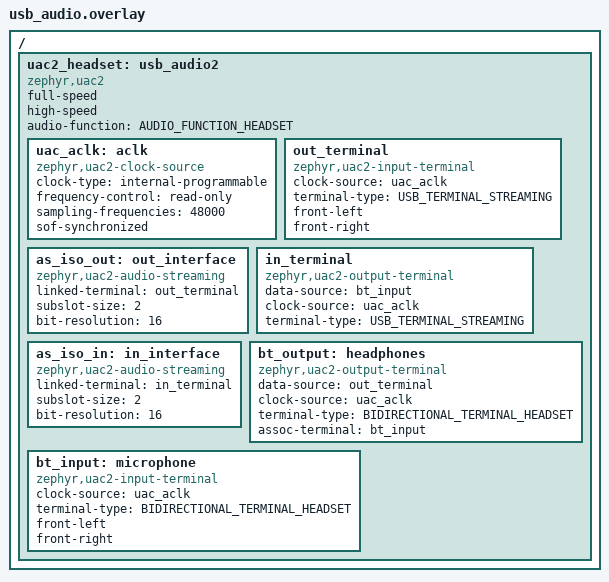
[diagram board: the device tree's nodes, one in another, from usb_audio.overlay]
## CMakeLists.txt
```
# SPDX-License-Identifier: Apache-2.0

cmake_minimum_required(VERSION 3.28.0)
find_package(Zephyr REQUIRED HINTS $ENV{ZEPHYR_BASE})
project(bluetooth_shell)

zephyr_library_include_directories(${ZEPHYR_BASE}/samples/bluetooth)

target_sources(app PRIVATE src/main.c)
```

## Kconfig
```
# Copyright (c) 2026 Nordic Semiconductor ASA
# SPDX-License-Identifier: Apache-2.0

mainmenu "Bluetooth Shell Test Application"

# LE Audio Controller settings for non-network core devices
if BT_AUDIO && BT_LL_SW_SPLIT

configdefault BT_CTLR_DATA_LENGTH_MAX
	default 251

# Set to high value to support large BASEs + extra data
configdefault BT_CTLR_SCAN_DATA_LEN_MAX
	default 1650

configdefault BT_CTLR_ADV_SYNC_SET
	default BT_CTLR_ADV_AUX_SET

configdefault BT_CTLR_ADV_DATA_LEN_MAX
	default 191

configdefault BT_CTLR_ADV_DATA_BUF_MAX
	default 6

# Match BT_BAP_BROADCAST_SRC_STREAM_COUNT in audio.conf
configdefault BT_CTLR_SYNC_ISO_STREAM_MAX
	default 2

# Match BT_BAP_BROADCAST_SNK_STREAM_COUNT in audio.conf
configdefault BT_CTLR_ADV_ISO_STREAM_MAX
	default 2

# Match BT_BAP_UNICAST_CLIENT_ASE_SRC_COUNT/BT_ASCS_MAX_ASE_SNK_COUNT audio.conf
configdefault BT_CTLR_ISOAL_SOURCES
	default 2

# BT_BAP_UNICAST_CLIENT_ASE_SNK_COUNT/BT_ASCS_MAX_ASE_SRC_COUNT in audio.conf
configdefault BT_CTLR_ISOAL_SINKS
	default 2

configdefault BT_CTLR_ISO_TX_BUFFER_SIZE
	default 255

configdefault BT_CTLR_ISO_TX_SDU_LEN_MAX
	default 247

endif # BT_AUDIO && BT_LL_SW_SPLIT

source "Kconfig.zephyr"
```

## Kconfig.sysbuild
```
# Copyright 2023-2024 Nordic Semiconductor ASA
# SPDX-License-Identifier: Apache-2.0

source "share/sysbuild/Kconfig"

config NET_CORE_BOARD
	string
	default "nrf5340dk/nrf5340/cpunet" if $(BOARD) = "nrf5340dk"
	default "nrf5340_audio_dk/nrf5340/cpunet" if $(BOARD) = "nrf5340_audio_dk"
	default "nrf5340bsim/nrf5340/cpunet" if $(BOARD_TARGET_STRING) = "NRF5340BSIM_NRF5340_CPUAPP"

config NET_CORE_IMAGE_HCI_IPC
	bool "HCI IPC image on network core"
	default y
	depends on NET_CORE_BOARD != ""
```

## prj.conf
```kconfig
CONFIG_TEST=y
CONFIG_TEST_LOGGING_DEFAULTS=n
CONFIG_BT=y
CONFIG_LOG=y
CONFIG_BT_CENTRAL=y
CONFIG_BT_PERIPHERAL=y
CONFIG_BT_PRIVACY=y
CONFIG_BT_SMP=y
CONFIG_BT_PASSKEY_KEYPRESS=y
CONFIG_BT_APP_PASSKEY=y
CONFIG_BT_ATT_PREPARE_COUNT=2
CONFIG_BT_GATT_CLIENT=y
CONFIG_BT_L2CAP_DYNAMIC_CHANNEL=y
CONFIG_BT_SHELL=y
CONFIG_BT_DEVICE_NAME="test shell"
CONFIG_BT_DEVICE_NAME_DYNAMIC=y
CONFIG_BT_L2CAP_TX_BUF_COUNT=4
CONFIG_BT_ID_MAX=2
CONFIG_BT_EATT=y
CONFIG_BT_L2CAP_ECRED=y
CONFIG_BT_GATT_DYNAMIC_DB=y
CONFIG_BT_GATT_NOTIFY_MULTIPLE=y
CONFIG_BT_HRS=y
CONFIG_BT_FILTER_ACCEPT_LIST=y
CONFIG_BT_REMOTE_INFO=y
CONFIG_BT_REMOTE_VERSION=y
CONFIG_BT_GATT_AUTO_DISCOVER_CCC=y

CONFIG_BT_SETTINGS=y
CONFIG_FLASH=y
CONFIG_FLASH_MAP=y
CONFIG_NVS=y
CONFIG_SETTINGS=y

CONFIG_BT_EXT_ADV=y
CONFIG_BT_EXT_ADV_LEGACY_SUPPORT=y
CONFIG_BT_PER_ADV=y
CONFIG_BT_PER_ADV_SYNC=y

CONFIG_BT_USER_DATA_LEN_UPDATE=y
CONFIG_BT_AUTO_DATA_LEN_UPDATE=y

CONFIG_BT_EAD=y

CONFIG_BT_USER_PHY_UPDATE=y

CONFIG_BT_ISO_BROADCASTER=y
CONFIG_BT_ISO_SYNC_RECEIVER=y
CONFIG_BT_ISO_CENTRAL=y
CONFIG_BT_ISO_PERIPHERAL=y

# Usage:
# `kernel log-level modulename severity`
# e.g.,
#
# kernel log-level bt_hci_core 0
# kernel log-level bt_l2cap 2
# kernel log-level bt_att 4
CONFIG_LOG_RUNTIME_FILTERING=y
```

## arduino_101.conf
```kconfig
CONFIG_BT=y
CONFIG_CONSOLE_HANDLER=y
CONFIG_BT_DEBUG_LOG=y
CONFIG_BT_CENTRAL=y
CONFIG_BT_PERIPHERAL=y
CONFIG_BT_PRIVACY=y
CONFIG_BT_SMP=y
CONFIG_BT_SIGNING=y
CONFIG_BT_ATT_PREPARE_COUNT=2
CONFIG_BT_GATT_CLIENT=y
CONFIG_BT_L2CAP_DYNAMIC_CHANNEL=y
CONFIG_BT_TINYCRYPT_ECC=y
CONFIG_CONSOLE_SHELL=y
CONFIG_BT_SHELL=y
CONFIG_BT_DEVICE_NAME="test shell"
CONFIG_BT_HRS=y
CONFIG_BT_L2CAP_TX_BUF_COUNT=6
CONFIG_BT_INTERNAL_STORAGE=y
CONFIG_FLASH=y
CONFIG_SPI=y
CONFIG_GPIO=y
CONFIG_FILE_SYSTEM=y
CONFIG_FILE_SYSTEM_FAT=y
CONFIG_DISK_ACCESS_FLASH=y
CONFIG_FILE_SYSTEM_SHELL=y
```

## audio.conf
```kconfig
# Increased stack due to settings API usage
CONFIG_SYSTEM_WORKQUEUE_STACK_SIZE=2048

# Needed for devices with many PAC records or large BASEs
CONFIG_BT_RX_STACK_SIZE=8192

CONFIG_TEST=y
CONFIG_TEST_LOGGING_DEFAULTS=n
CONFIG_BT=y
CONFIG_BT_SMP=y
CONFIG_BT_TESTING=y
CONFIG_BT_CENTRAL=y
CONFIG_BT_ISO_CENTRAL=y
CONFIG_BT_EXT_ADV=y
CONFIG_BT_PER_ADV_SYNC=y
CONFIG_BT_ISO_SYNC_RECEIVER=y
CONFIG_BT_PERIPHERAL=y
CONFIG_BT_PRIVACY=y
CONFIG_BT_GATT_CLIENT=y
CONFIG_BT_GATT_DYNAMIC_DB=y
CONFIG_BT_GATT_AUTO_DISCOVER_CCC=y
CONFIG_BT_GATT_AUTO_UPDATE_MTU=y
CONFIG_BT_L2CAP_ECRED=y
CONFIG_BT_APP_PASSKEY=y
CONFIG_BT_ATT_PREPARE_COUNT=5
# Long writes come from one client at a time, so let it use the whole pool
CONFIG_BT_ATT_PREPARE_COUNT_PER_CONN=5
CONFIG_BT_SHELL=y
CONFIG_BT_DEVICE_NAME="audio test shell"
CONFIG_BT_DEVICE_NAME_DYNAMIC=y
# TBS Client may require up to 12 buffers
CONFIG_BT_ATT_TX_COUNT=12
CONFIG_BT_ID_MAX=2
CONFIG_BT_FILTER_ACCEPT_LIST=y
CONFIG_BT_REMOTE_INFO=y
CONFIG_BT_REMOTE_VERSION=y
CONFIG_BT_MAX_CONN=3
CONFIG_BT_MAX_PAIRED=3
CONFIG_BT_KEYS_OVERWRITE_OLDEST=y

CONFIG_BT_L2CAP_TX_MTU=128
CONFIG_BT_BUF_ACL_RX_SIZE=255
CONFIG_BT_BUF_ACL_TX_SIZE=251
CONFIG_BT_SETTINGS=y
CONFIG_FLASH=y
CONFIG_FLASH_MAP=y
CONFIG_NVS=y
CONFIG_SETTINGS=y

CONFIG_BT_USER_DATA_LEN_UPDATE=y
CONFIG_BT_AUTO_DATA_LEN_UPDATE=y

CONFIG_BT_USER_PHY_UPDATE=y

CONFIG_BT_GAP_AUTO_UPDATE_CONN_PARAMS=n
# Set preferred values based on BT_BAP_CONN_PARAM_RELAXED
CONFIG_BT_PERIPHERAL_PREF_MIN_INT=50
CONFIG_BT_PERIPHERAL_PREF_MAX_INT=70
CONFIG_BT_PERIPHERAL_PREF_LATENCY=0
CONFIG_BT_PERIPHERAL_PREF_TIMEOUT=400

CONFIG_BT_PER_ADV_SYNC_TRANSFER_RECEIVER=y
CONFIG_BT_PER_ADV_SYNC_TRANSFER_SENDER=y

# Support an ISO channel per ASE
CONFIG_BT_ISO_BROADCASTER=y
CONFIG_BT_ISO_PERIPHERAL=y
CONFIG_BT_ISO_MAX_CHAN=2
CONFIG_BT_ISO_TEST_PARAMS=y
CONFIG_BT_ISO_TX_BUF_COUNT=10
CONFIG_BT_ISO_RX_BUF_COUNT=20
CONFIG_BT_ISO_TX_MTU=310
CONFIG_BT_ISO_RX_MTU=310

CONFIG_BT_AUDIO=y
CONFIG_BT_BAP_UNICAST_SERVER=y

CONFIG_BT_BAP_UNICAST_CLIENT=y
CONFIG_BT_BAP_UNICAST_CLIENT_GROUP_STREAM_COUNT=2
CONFIG_BT_BAP_UNICAST_CLIENT_ASE_SNK_COUNT=2
CONFIG_BT_BAP_UNICAST_CLIENT_ASE_SRC_COUNT=2

CONFIG_BT_AUDIO_CODEC_CFG_MAX_METADATA_SIZE=255
CONFIG_BT_AUDIO_CODEC_CAP_MAX_METADATA_SIZE=255

CONFIG_BT_ASCS=y
CONFIG_BT_PAC_SNK=y
CONFIG_BT_ASCS_MAX_ASE_SNK_COUNT=2
CONFIG_BT_PAC_SRC=y
CONFIG_BT_ASCS_MAX_ASE_SRC_COUNT=2
CONFIG_BT_BAP_BROADCAST_SOURCE=y
CONFIG_BT_BAP_BROADCAST_SRC_SUBGROUP_COUNT=1
CONFIG_BT_BAP_BROADCAST_SRC_STREAM_COUNT=2

CONFIG_BT_BAP_BROADCAST_SINK=y
CONFIG_BT_BAP_BROADCAST_SNK_SUBGROUP_COUNT=1
CONFIG_BT_BAP_BROADCAST_SNK_STREAM_COUNT=2

CONFIG_BT_VOCS_MAX_INSTANCE_COUNT=1
CONFIG_BT_VOCS_CLIENT_MAX_INSTANCE_COUNT=1

CONFIG_BT_AICS_MAX_INSTANCE_COUNT=2
CONFIG_BT_AICS_CLIENT_MAX_INSTANCE_COUNT=2

CONFIG_BT_VCP_VOL_REND=y
CONFIG_BT_VCP_VOL_REND_VOCS_INSTANCE_COUNT=1
CONFIG_BT_VCP_VOL_REND_AICS_INSTANCE_COUNT=1
CONFIG_BT_VCP_VOL_CTLR=y
CONFIG_BT_VCP_VOL_CTLR_MAX_VOCS_INST=1
CONFIG_BT_VCP_VOL_CTLR_MAX_AICS_INST=1
CONFIG_BT_VCP_VOL_REND_VOL_FLAGS_NOTIFIABLE=y

CONFIG_BT_MICP_MIC_DEV=y
CONFIG_BT_MICP_MIC_DEV_AICS_INSTANCE_COUNT=1
CONFIG_BT_MICP_MIC_CTLR=y
CONFIG_BT_MICP_MIC_CTLR_MAX_AICS_INST=1

# Coordinated Set Identification
CONFIG_BT_CSIP_SET_MEMBER=y
CONFIG_BT_CSIP_SET_MEMBER_SIRK_NOTIFIABLE=y
CONFIG_BT_CSIP_SET_MEMBER_SIZE_NOTIFIABLE=y
CONFIG_BT_CSIP_SET_COORDINATOR=y
CONFIG_BT_CSIP_SET_COORDINATOR_MAX_CSIS_INSTANCES=2

CONFIG_MCTL=y
CONFIG_MCTL_LOCAL_PLAYER_CONTROL=y
CONFIG_MCTL_LOCAL_PLAYER_LOCAL_CONTROL=y
CONFIG_MCTL_LOCAL_PLAYER_REMOTE_CONTROL=y
CONFIG_MCTL_REMOTE_PLAYER_CONTROL=y
CONFIG_MCTL_REMOTE_PLAYER_CONTROL_OBJECTS=y

CONFIG_BT_MPL=y
CONFIG_BT_MPL_OBJECTS=y

# Call Control
CONFIG_BT_CCP_CALL_CONTROL_SERVER=y
CONFIG_BT_CCP_CALL_CONTROL_SERVER_BEARER_COUNT=2
CONFIG_BT_TBS=y
CONFIG_BT_TBS_BEARER_COUNT=1
CONFIG_BT_CCP_CALL_CONTROL_CLIENT=y
CONFIG_BT_CCP_CALL_CONTROL_CLIENT_BEARER_COUNT=2
CONFIG_BT_TBS_CLIENT_TBS=y
CONFIG_BT_TBS_CLIENT_GTBS=y
CONFIG_BT_TBS_CLIENT_MAX_CALLS=2

CONFIG_BT_MCS=y
CONFIG_BT_MCC=y
CONFIG_BT_MCC_OTS=y
CONFIG_UTF8=y

# Object Transfer
CONFIG_BT_OTS=y
CONFIG_BT_OTS_SECONDARY_SVC=y
CONFIG_BT_OTS_CLIENT=y

CONFIG_BT_BAP_SCAN_DELEGATOR=y
CONFIG_BT_BAP_BASS_MAX_SUBGROUPS=1
CONFIG_BT_BAP_BROADCAST_ASSISTANT=y
CONFIG_BT_BAP_BROADCAST_ASSISTANT_RECV_STATE_COUNT=2

# IAS
CONFIG_BT_IAS=y
CONFIG_BT_IAS_CLIENT=y

CONFIG_BT_HAS=y
CONFIG_BT_HAS_PRESET_NAME_DYNAMIC=y
CONFIG_BT_HAS_PRESET_COUNT=2
CONFIG_BT_HAS_CLIENT=y
CONFIG_BT_HAS_FEATURES_NOTIFIABLE=y

# Common Audio Profile
CONFIG_BT_CAP_ACCEPTOR=y
CONFIG_BT_CAP_ACCEPTOR_SET_MEMBER=y
CONFIG_BT_CAP_INITIATOR=y
CONFIG_BT_CAP_COMMANDER=y
CONFIG_BT_CAP_HANDOVER=y

# Telephone and Media Audio Profile
CONFIG_BT_TMAP=y

# Public Broadcast Profile
CONFIG_BT_PBP=y

CONFIG_BT_PACS_SUPPORTED_CONTEXT_NOTIFIABLE=y
CONFIG_BT_PAC_SNK_LOC_NOTIFIABLE=y
CONFIG_BT_PAC_SRC_LOC_NOTIFIABLE=y
CONFIG_BT_PAC_SRC_NOTIFIABLE=y
CONFIG_BT_PAC_SNK_NOTIFIABLE=y
CONFIG_BT_PAC_SNK_LOC_WRITEABLE=y
CONFIG_BT_PAC_SRC_LOC_WRITEABLE=y

# Gaming Audio Profile
CONFIG_BT_GMAP=y

# DEBUGGING
CONFIG_LOG=y
# CONFIG_BT_AUDIO_LOG_LEVEL_DBG=y
# CONFIG_BT_AUDIO_CODEC_LOG_LEVEL_DBG=y
# CONFIG_BT_AICS_LOG_LEVEL_DBG=y
# CONFIG_BT_AICS_CLIENT_LOG_LEVEL_DBG=y
# CONFIG_BT_ASCS_LOG_LEVEL_DBG=y
# CONFIG_BT_BAP_BROADCAST_SOURCE_LOG_LEVEL_DBG=y
# CONFIG_BT_BAP_BROADCAST_SINK_LOG_LEVEL_DBG=y
# CONFIG_BT_BAP_BROADCAST_ASSISTANT_LOG_LEVEL_DBG=y
# CONFIG_BT_BAP_ISO_LOG_LEVEL_DBG=y
# CONFIG_BT_BAP_SCAN_DELEGATOR_LOG_LEVEL_DBG=y
# CONFIG_BT_BAP_STREAM_LOG_LEVEL_DBG=y
# CONFIG_BT_BAP_UNICAST_SERVER_LOG_LEVEL_DBG=y
# CONFIG_BT_BAP_UNICAST_CLIENT_LOG_LEVEL_DBG=y
# CONFIG_BT_CAP_ACCEPTOR_LOG_LEVEL_DBG=y
# CONFIG_BT_CAP_COMMANDER_LOG_LEVEL_DBG=y
# CONFIG_BT_CAP_COMMON_LOG_LEVEL_DBG=y
# CONFIG_BT_CAP_INITIATOR_LOG_LEVEL_DBG=y
# CONFIG_BT_CSIP_SET_COORDINATOR_LOG_LEVEL_DBG=y
# CONFIG_BT_CSIP_SET_MEMBER_LOG_LEVEL_DBG=y
# CONFIG_BT_GMAP_LOG_LEVEL_DBG=y
# CONFIG_BT_HAS_LOG_LEVEL_DBG=y
# CONFIG_BT_HAS_CLIENT_LOG_LEVEL_DBG=y
# CONFIG_BT_MCS_LOG_LEVEL_DBG=y
# CONFIG_BT_MCC_LOG_LEVEL_DBG=y
# CONFIG_BT_MICP_MIC_CTLR_LOG_LEVEL_DBG=y
# CONFIG_BT_MICP_MIC_DEV_LOG_LEVEL_DBG=y
# CONFIG_BT_MPL_LOG_LEVEL_DBG=y
# CONFIG_BT_OTS_LOG_LEVEL_DBG=y
# CONFIG_BT_OTS_CLIENT_LOG_LEVEL_DBG=y
# CONFIG_BT_PACS_LOG_LEVEL_DBG=y
# CONFIG_BT_TBS_LOG_LEVEL_DBG=y
# CONFIG_BT_TBS_CLIENT_LOG_LEVEL_DBG=y
# CONFIG_BT_TMAP_LOG_LEVEL_DBG=y
# CONFIG_BT_VCP_VOL_CTLR_LOG_LEVEL_DBG=y
# CONFIG_BT_VCP_VOL_REND_LOG_LEVEL_DBG=y
# CONFIG_BT_VOCS_CLIENT_LOG_LEVEL_DBG=y
# CONFIG_BT_VOCS_LOG_LEVEL_DBG=y
# CONFIG_MCTL_LOG_LEVEL_DBG=y

# Controller settings
CONFIG_BT_CTLR_DATA_LENGTH_MAX=251

# Support having both a connectable and a non-connectable set
CONFIG_BT_CTLR_ADV_SET=2
CONFIG_BT_CTLR_ADV_AUX_SET=2
CONFIG_BT_CTLR_ADV_SYNC_SET=2
CONFIG_BT_CTLR_ADV_DATA_LEN_MAX=191
CONFIG_BT_CTLR_ADV_DATA_BUF_MAX=6

CONFIG_BT_CTLR_SCAN_DATA_LEN_MAX=1650

# Match the number of broadcast streams supported in BAP
CONFIG_BT_CTLR_SYNC_ISO_STREAM_MAX=2
CONFIG_BT_CTLR_ADV_ISO_STREAM_MAX=2

# Match the number of unicast streams supported in BAP
CONFIG_BT_CTLR_ISOAL_SOURCES=2
CONFIG_BT_CTLR_ISOAL_SINKS=2
```

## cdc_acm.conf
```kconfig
CONFIG_USB_DEVICE_STACK_NEXT=y
CONFIG_CDC_ACM_SERIAL_INITIALIZE_AT_BOOT=y
CONFIG_CDC_ACM_SERIAL_PRODUCT_STRING="Zephyr BT Shell"

CONFIG_UART_LINE_CTRL=y
CONFIG_SHELL_BACKEND_SERIAL_CHECK_DTR=y
```

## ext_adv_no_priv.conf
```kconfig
CONFIG_BT_EXT_ADV=y
CONFIG_BT_PRIVACY=n
```

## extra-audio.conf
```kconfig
# Needed for devices with many PAC records or large BASEs
CONFIG_BT_RX_STACK_SIZE=8192

CONFIG_BT_TESTING=y

# Support having both a connectable and a non-connectable set
CONFIG_BT_EXT_ADV_MAX_ADV_SET=2
CONFIG_BT_GATT_AUTO_UPDATE_MTU=y
CONFIG_BT_ATT_PREPARE_COUNT=5
# Long writes come from one client at a time, so let it use the whole pool
CONFIG_BT_ATT_PREPARE_COUNT_PER_CONN=5
CONFIG_BT_DEVICE_NAME="audio test shell"
# TBS Client may require up to 12 buffers
CONFIG_BT_ATT_TX_COUNT=12
CONFIG_BT_MAX_CONN=3
CONFIG_BT_MAX_PAIRED=3
CONFIG_BT_KEYS_OVERWRITE_OLDEST=y

CONFIG_BT_L2CAP_TX_MTU=128
CONFIG_BT_BUF_ACL_RX_SIZE=255
CONFIG_BT_BUF_ACL_TX_SIZE=251

# Set preferred values based on BT_BAP_CONN_PARAM_RELAXED
CONFIG_BT_GAP_AUTO_UPDATE_CONN_PARAMS=n
CONFIG_BT_PERIPHERAL_PREF_MIN_INT=50
CONFIG_BT_PERIPHERAL_PREF_MAX_INT=70
CONFIG_BT_PERIPHERAL_PREF_LATENCY=0
CONFIG_BT_PERIPHERAL_PREF_TIMEOUT=400

CONFIG_BT_PER_ADV_SYNC_TRANSFER_RECEIVER=y
CONFIG_BT_PER_ADV_SYNC_TRANSFER_SENDER=y

# Support an ISO channel per ASE
CONFIG_BT_ISO_MAX_CHAN=4
CONFIG_BT_ISO_TEST_PARAMS=y
CONFIG_BT_ISO_TX_BUF_COUNT=10
CONFIG_BT_ISO_RX_BUF_COUNT=20
CONFIG_BT_ISO_TX_MTU=310
CONFIG_BT_ISO_RX_MTU=310

CONFIG_BT_AUDIO=y
CONFIG_BT_BAP_UNICAST_SERVER=y

CONFIG_BT_BAP_UNICAST_CLIENT=y
CONFIG_BT_BAP_UNICAST_CLIENT_GROUP_STREAM_COUNT=4
CONFIG_BT_BAP_UNICAST_CLIENT_ASE_SNK_COUNT=2
CONFIG_BT_BAP_UNICAST_CLIENT_ASE_SRC_COUNT=2

CONFIG_BT_AUDIO_CODEC_CFG_MAX_METADATA_SIZE=255
CONFIG_BT_AUDIO_CODEC_CAP_MAX_METADATA_SIZE=255

CONFIG_BT_ASCS=y
CONFIG_BT_PAC_SNK=y
CONFIG_BT_ASCS_MAX_ASE_SNK_COUNT=2
CONFIG_BT_PAC_SRC=y
CONFIG_BT_ASCS_MAX_ASE_SRC_COUNT=2
CONFIG_BT_BAP_BROADCAST_SOURCE=y
CONFIG_BT_BAP_BROADCAST_SRC_SUBGROUP_COUNT=1
CONFIG_BT_BAP_BROADCAST_SRC_STREAM_COUNT=2

CONFIG_BT_BAP_BROADCAST_SINK=y
CONFIG_BT_BAP_BROADCAST_SNK_SUBGROUP_COUNT=1
CONFIG_BT_BAP_BROADCAST_SNK_STREAM_COUNT=2

CONFIG_BT_VOCS_MAX_INSTANCE_COUNT=1
CONFIG_BT_VOCS_CLIENT_MAX_INSTANCE_COUNT=1

CONFIG_BT_AICS_MAX_INSTANCE_COUNT=2
CONFIG_BT_AICS_CLIENT_MAX_INSTANCE_COUNT=2

CONFIG_BT_VCP_VOL_REND=y
CONFIG_BT_VCP_VOL_REND_VOCS_INSTANCE_COUNT=1
CONFIG_BT_VCP_VOL_REND_AICS_INSTANCE_COUNT=1
CONFIG_BT_VCP_VOL_CTLR=y
CONFIG_BT_VCP_VOL_CTLR_MAX_VOCS_INST=1
CONFIG_BT_VCP_VOL_CTLR_MAX_AICS_INST=1
CONFIG_BT_VCP_VOL_REND_VOL_FLAGS_NOTIFIABLE=y

CONFIG_BT_MICP_MIC_DEV=y
CONFIG_BT_MICP_MIC_DEV_AICS_INSTANCE_COUNT=1
CONFIG_BT_MICP_MIC_CTLR=y
CONFIG_BT_MICP_MIC_CTLR_MAX_AICS_INST=1

# Coordinated Set Identification
CONFIG_BT_CSIP_SET_MEMBER=y
CONFIG_BT_CSIP_SET_MEMBER_SIZE_SUPPORT=y
CONFIG_BT_CSIP_SET_MEMBER_LOCK_SUPPORT=y
CONFIG_BT_CSIP_SET_MEMBER_RANK_SUPPORT=y
CONFIG_BT_CSIP_SET_MEMBER_SIRK_NOTIFIABLE=y
CONFIG_BT_CSIP_SET_MEMBER_SIZE_NOTIFIABLE=y
CONFIG_BT_CSIP_SET_COORDINATOR=y
CONFIG_BT_CSIP_SET_COORDINATOR_MAX_CSIS_INSTANCES=2

CONFIG_BT_MCP_MEDIA_CONTROL_SERVER=y
CONFIG_BT_MCP_MEDIA_CONTROL_SERVER_OBJECTS=y

# Call Control
CONFIG_BT_CCP_CALL_CONTROL_SERVER=y
CONFIG_BT_CCP_CALL_CONTROL_SERVER_BEARER_COUNT=2
CONFIG_BT_CCP_CALL_CONTROL_SERVER_BEARER_SIGNAL_STRENGTH=y
CONFIG_BT_TBS=y
CONFIG_BT_TBS_BEARER_COUNT=1
CONFIG_BT_CCP_CALL_CONTROL_CLIENT=y
CONFIG_BT_CCP_CALL_CONTROL_CLIENT_BEARER_COUNT=2
CONFIG_BT_TBS_CLIENT_TBS=y
CONFIG_BT_TBS_CLIENT_GTBS=y
CONFIG_BT_TBS_CLIENT_MAX_CALLS=2

CONFIG_BT_MCS=y
CONFIG_BT_MCC=y
CONFIG_BT_MCC_OTS=y
CONFIG_UTF8=y

# Object Transfer
CONFIG_BT_OTS=y
CONFIG_BT_OTS_MAX_OBJ_CNT=20
CONFIG_BT_OTS_SECONDARY_SVC=y
CONFIG_BT_OTS_CLIENT=y

CONFIG_BT_BAP_SCAN_DELEGATOR=y
CONFIG_BT_BAP_BASS_MAX_SUBGROUPS=1
CONFIG_BT_BAP_BROADCAST_ASSISTANT=y
CONFIG_BT_BAP_BROADCAST_ASSISTANT_RECV_STATE_COUNT=2

# IAS
CONFIG_BT_IAS=y
CONFIG_BT_IAS_CLIENT=y

CONFIG_BT_HAS=y
CONFIG_BT_HAS_PRESET_NAME_DYNAMIC=y
CONFIG_BT_HAS_PRESET_COUNT=2
CONFIG_BT_HAS_CLIENT=y
CONFIG_BT_HAS_FEATURES_NOTIFIABLE=y

# Common Audio Profile
CONFIG_BT_CAP_ACCEPTOR=y
CONFIG_BT_CAP_ACCEPTOR_SET_MEMBER=y
CONFIG_BT_CAP_INITIATOR=y
CONFIG_BT_CAP_COMMANDER=y
CONFIG_BT_CAP_HANDOVER=y

# Telephone and Media Audio Profile
CONFIG_BT_TMAP=y

# Public Broadcast Profile
CONFIG_BT_PBP=y

CONFIG_BT_PACS_SUPPORTED_CONTEXT_NOTIFIABLE=y
CONFIG_BT_PAC_SNK_LOC_NOTIFIABLE=y
CONFIG_BT_PAC_SRC_LOC_NOTIFIABLE=y
CONFIG_BT_PAC_SRC_NOTIFIABLE=y
CONFIG_BT_PAC_SNK_NOTIFIABLE=y
CONFIG_BT_PAC_SNK_LOC_WRITEABLE=y
CONFIG_BT_PAC_SRC_LOC_WRITEABLE=y

# Gaming Audio Profile
CONFIG_BT_GMAP=y

# DEBUGGING
# CONFIG_BT_AUDIO_LOG_LEVEL_DBG=y
# CONFIG_BT_AUDIO_CODEC_LOG_LEVEL_DBG=y
# CONFIG_BT_AICS_LOG_LEVEL_DBG=y
# CONFIG_BT_AICS_CLIENT_LOG_LEVEL_DBG=y
# CONFIG_BT_ASCS_LOG_LEVEL_DBG=y
# CONFIG_BT_BAP_BROADCAST_SOURCE_LOG_LEVEL_DBG=y
# CONFIG_BT_BAP_BROADCAST_SINK_LOG_LEVEL_DBG=y
# CONFIG_BT_BAP_BROADCAST_ASSISTANT_LOG_LEVEL_DBG=y
# CONFIG_BT_BAP_ISO_LOG_LEVEL_DBG=y
# CONFIG_BT_BAP_SCAN_DELEGATOR_LOG_LEVEL_DBG=y
# CONFIG_BT_BAP_STREAM_LOG_LEVEL_DBG=y
# CONFIG_BT_BAP_UNICAST_SERVER_LOG_LEVEL_DBG=y
# CONFIG_BT_BAP_UNICAST_CLIENT_LOG_LEVEL_DBG=y
# CONFIG_BT_CAP_ACCEPTOR_LOG_LEVEL_DBG=y
# CONFIG_BT_CAP_COMMANDER_LOG_LEVEL_DBG=y
# CONFIG_BT_CAP_COMMON_LOG_LEVEL_DBG=y
# CONFIG_BT_CAP_HANDOVER_LOG_LEVEL_DBG=y
# CONFIG_BT_CAP_INITIATOR_LOG_LEVEL_DBG=y
# CONFIG_BT_CSIP_SET_COORDINATOR_LOG_LEVEL_DBG=y
# CONFIG_BT_CSIP_SET_MEMBER_LOG_LEVEL_DBG=y
# CONFIG_BT_GMAP_LOG_LEVEL_DBG=y
# CONFIG_BT_HAS_LOG_LEVEL_DBG=y
# CONFIG_BT_HAS_CLIENT_LOG_LEVEL_DBG=y
# CONFIG_BT_MCS_LOG_LEVEL_DBG=y
# CONFIG_BT_MCC_LOG_LEVEL_DBG=y
# CONFIG_BT_MICP_MIC_CTLR_LOG_LEVEL_DBG=y
# CONFIG_BT_MICP_MIC_DEV_LOG_LEVEL_DBG=y
# CONFIG_BT_MCP_MEDIA_CONTROL_SERVER_LOG_LEVEL_DBG=y
# CONFIG_BT_OTS_LOG_LEVEL_DBG=y
# CONFIG_BT_OTS_CLIENT_LOG_LEVEL_DBG=y
# CONFIG_BT_PACS_LOG_LEVEL_DBG=y
# CONFIG_BT_TBS_LOG_LEVEL_DBG=y
# CONFIG_BT_TBS_CLIENT_LOG_LEVEL_DBG=y
# CONFIG_BT_TMAP_LOG_LEVEL_DBG=y
# CONFIG_BT_VCP_VOL_CTLR_LOG_LEVEL_DBG=y
# CONFIG_BT_VCP_VOL_REND_LOG_LEVEL_DBG=y
# CONFIG_BT_VOCS_CLIENT_LOG_LEVEL_DBG=y
# CONFIG_BT_VOCS_LOG_LEVEL_DBG=y
```

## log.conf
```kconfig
# Increased stack due to settings API usage
CONFIG_SYSTEM_WORKQUEUE_STACK_SIZE=2048
CONFIG_SYSTEM_WORKQUEUE_STACK_IGNORE_MIN=y

CONFIG_TEST=y
CONFIG_TEST_LOGGING_DEFAULTS=n
CONFIG_BT=y
CONFIG_BT_CENTRAL=y
CONFIG_BT_PERIPHERAL=y
CONFIG_BT_PRIVACY=y
CONFIG_BT_SMP=y
CONFIG_BT_APP_PASSKEY=y
CONFIG_BT_ATT_PREPARE_COUNT=2
CONFIG_BT_GATT_CLIENT=y
CONFIG_BT_L2CAP_DYNAMIC_CHANNEL=y
CONFIG_BT_SHELL=y
CONFIG_BT_DEVICE_NAME="log test shell"
CONFIG_BT_DEVICE_NAME_DYNAMIC=y
CONFIG_BT_L2CAP_TX_BUF_COUNT=4
CONFIG_BT_ID_MAX=2
CONFIG_BT_EATT=y
CONFIG_BT_L2CAP_ECRED=y
CONFIG_BT_GATT_DYNAMIC_DB=y
CONFIG_BT_GATT_NOTIFY_MULTIPLE=y
CONFIG_BT_HRS=y
CONFIG_BT_FILTER_ACCEPT_LIST=y
CONFIG_BT_REMOTE_INFO=y
CONFIG_BT_REMOTE_VERSION=y
CONFIG_BT_GATT_AUTO_DISCOVER_CCC=y

# Disable BT logging and enable general logging
CONFIG_BT_LOG_LEVEL_OFF=y
CONFIG_LOG=y

CONFIG_BT_SETTINGS=y
CONFIG_FLASH=y
CONFIG_FLASH_MAP=y
CONFIG_NVS=y
CONFIG_SETTINGS=y

CONFIG_BT_EXT_ADV=y
CONFIG_BT_EXT_ADV_LEGACY_SUPPORT=y
CONFIG_BT_PER_ADV=y
CONFIG_BT_PER_ADV_SYNC=y

CONFIG_BT_USER_DATA_LEN_UPDATE=y
CONFIG_BT_AUTO_DATA_LEN_UPDATE=y

CONFIG_BT_USER_PHY_UPDATE=y

CONFIG_BT_ISO_BROADCASTER=y
CONFIG_BT_ISO_SYNC_RECEIVER=y
CONFIG_BT_ISO_CENTRAL=y
CONFIG_BT_ISO_PERIPHERAL=y

# Usage:
# `kernel log-level modulename severity`
# e.g.,
#
# kernel log-level bt_hci_core 0
# kernel log-level bt_l2cap 2
# kernel log-level bt_att 4
CONFIG_LOG_RUNTIME_FILTERING=y
```

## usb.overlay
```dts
/*
 * Copyright (c) 2021 Nordic Semiconductor ASA
 *
 * SPDX-License-Identifier: Apache-2.0
 */

/ {
	chosen {
		zephyr,shell-uart = &cdc_acm_uart0;
	};
};

&zephyr_udc0 {
	cdc_acm_uart0: cdc_acm_uart0 {
		compatible = "zephyr,cdc-acm-uart";
	};
};
```

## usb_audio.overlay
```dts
/*
 * Copyright (c) 2025 Nordic Semiconductor ASA
 *
 * SPDX-License-Identifier: Apache-2.0
 */

#include <zephyr/dt-bindings/usb/audio.h>

/ {
	uac2_headset: usb_audio2 {
		compatible = "zephyr,uac2";
		full-speed;
		high-speed;
		audio-function = <AUDIO_FUNCTION_HEADSET>;
		status = "okay";

		/* Clock supporting 48KHz
		 *
		 * Since the incoming audio may be between 8 and 48 KHz, we always upsample to 48KHz
		 */
		uac_aclk: aclk {
			compatible = "zephyr,uac2-clock-source";
			clock-type = "internal-programmable";
			frequency-control = "read-only";
			sampling-frequencies = <48000>;
			/* Falsely claim synchronous audio because we
			 * currently don't calculate feedback value
			 */
			sof-synchronized;
		};

		/* USB Audio terminal from USB host to USB device */
		out_terminal: out_terminal {
			compatible = "zephyr,uac2-input-terminal";
			clock-source = <&uac_aclk>;
			terminal-type = <USB_TERMINAL_STREAMING>;
			front-left;
			front-right;
		};

		as_iso_out: out_interface {
			compatible = "zephyr,uac2-audio-streaming";
			linked-terminal = <&out_terminal>;
			subslot-size = <2>;
			bit-resolution = <16>;
		};

		/* USB Audio terminal from USB device to USB host */
		in_terminal: in_terminal {
			compatible = "zephyr,uac2-output-terminal";
			data-source = <&bt_input>;
			clock-source = <&uac_aclk>;
			terminal-type = <USB_TERMINAL_STREAMING>;
		};

		as_iso_in: in_interface {
			compatible = "zephyr,uac2-audio-streaming";
			linked-terminal = <&in_terminal>;
			subslot-size = <2>;
			bit-resolution = <16>;
		};

		/* The bt_output terminal defines what we are sending over Bluetooth */
		bt_output: headphones {
			compatible = "zephyr,uac2-output-terminal";
			data-source = <&out_terminal>;
			clock-source = <&uac_aclk>;
			terminal-type = <BIDIRECTIONAL_TERMINAL_HEADSET>;
			assoc-terminal = <&bt_input>;
		};

		/* The bt_input terminal defines what we are receiving over Bluetooth */
		bt_input: microphone {
			compatible = "zephyr,uac2-input-terminal";
			clock-source = <&uac_aclk>;
			terminal-type = <BIDIRECTIONAL_TERMINAL_HEADSET>;
			/* Circular reference, macros will figure it out and
			 * provide correct associated terminal ID because the
			 * terminals associations are always 1-to-1.
			 *
			 * assoc-terminal = <&bt_output>;
			 */
			front-left;
			front-right;
		};
	};
};
```

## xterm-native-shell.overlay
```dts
/* Copyright (c) 2024 Nordic Semiconductor
 * SPDX-License-Identifier: Apache-2.0
 */
/ {
	chosen {
		zephyr,console = &uart0;
		zephyr,shell-uart = &uart0;
	};
};

/* Use the PTY driver instead of the UART peripheral emulation that is now the
 * default on nrf52_bsim.
 */

&uart1 {
	compatible = "zephyr,native-pty-uart";
	status = "disabled";
	/delete-property/ pinctrl-0;
	/delete-property/ pinctrl-1;
	/delete-property/ pinctrl-names;

	bt_hci_uart: bt_hci_uart {
		compatible = "zephyr,bt-hci-uart";
		status = "disabled";
	};
};

&uart0 {
	compatible = "zephyr,native-pty-uart";
	status = "okay";
	/delete-property/ pinctrl-0;
	/delete-property/ pinctrl-1;
	/delete-property/ pinctrl-names;
};
```

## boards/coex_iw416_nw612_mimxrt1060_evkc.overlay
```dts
/*
 * Copyright 2025 NXP
 *
 * SPDX-License-Identifier: Apache-2.0
 */

&m2_hci_bt_uart {
	bt_hci_uart: bt_hci_uart {
	 m2_bt_module: m2_bt_module {
		/delete-property/ sdio-reset-gpios;
		/delete-property/ w-disable-gpios;
		};
	};
};

&usdhc1 {
	nxp_wifi {
		pwr-gpios = <&gpio1 19 GPIO_ACTIVE_HIGH>;
		sd-gpios = <&gpio1 24 GPIO_ACTIVE_HIGH>;
	};
};
```

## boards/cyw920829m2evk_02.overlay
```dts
/* SPDX-License-Identifier: Apache-2.0 */

uart2: &scb2 {
	hw-flow-control;
	pinctrl-0 = <&p3_3_scb2_uart_tx &p3_2_scb2_uart_rx &p3_1_scb2_uart_rts &p3_0_scb2_uart_cts>;
};
```

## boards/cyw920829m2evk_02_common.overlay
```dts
/*
 * SPDX-FileCopyrightText: Copyright (c) 2026 Infineon Technologies AG,
 * SPDX-FileCopyrightText: or an affiliate of Infineon Technologies AG. All rights reserved.
 *
 * SPDX-License-Identifier: Apache-2.0
 */

uart2: &scb2 {
	hw-flow-control;
	pinctrl-0 = <&p3_3_scb2_uart_tx &p3_2_scb2_uart_rx &p3_1_scb2_uart_rts &p3_0_scb2_uart_cts>;
};
```

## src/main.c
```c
/** @file
 *  @brief Interactive Bluetooth LE shell application
 *
 *  Application allows implement Bluetooth LE functional commands performing
 *  simple diagnostic interaction between LE host stack and LE controller
 */

/*
 * Copyright (c) 2017 Nordic Semiconductor ASA
 * Copyright (c) 2015-2016 Intel Corporation
 *
 * SPDX-License-Identifier: Apache-2.0
 */

#include <errno.h>
#include <zephyr/types.h>
#include <stddef.h>
#include <stdlib.h>
#include <string.h>
#include <zephyr/sys/printk.h>
#include <zephyr/sys/byteorder.h>
#include <zephyr/kernel.h>
#include <zephyr/usb/usb_device.h>
#include <zephyr/drivers/uart.h>

#include <zephyr/shell/shell.h>

#include <zephyr/bluetooth/hci.h>
#include <zephyr/bluetooth/bluetooth.h>
#include <zephyr/bluetooth/uuid.h>
#include <zephyr/bluetooth/services/hrs.h>

#define DEVICE_NAME CONFIG_BT_DEVICE_NAME

#if defined(CONFIG_BT_HRS)
static bool hrs_simulate;

static const struct bt_data ad[] = {
	BT_DATA_BYTES(BT_DATA_FLAGS, (BT_LE_AD_GENERAL | BT_LE_AD_NO_BREDR)),
	BT_DATA_BYTES(BT_DATA_UUID16_ALL,
		      BT_UUID_16_ENCODE(BT_UUID_HRS_VAL),
		      BT_UUID_16_ENCODE(BT_UUID_BAS_VAL),
		      BT_UUID_16_ENCODE(BT_UUID_DIS_VAL)),
};

static int cmd_hrs_simulate(const struct shell *sh,
			    size_t argc, char *argv[])
{
	static bool hrs_registered;
	int err;

	if (!strcmp(argv[1], "on")) {
		if (!hrs_registered && IS_ENABLED(CONFIG_BT_BROADCASTER)) {
			shell_print(sh, "Registering HRS Service");
			hrs_registered = true;
			err = bt_le_adv_start(BT_LE_ADV_CONN_FAST_1, ad,
					      ARRAY_SIZE(ad), NULL, 0);
			if (err) {
				shell_error(sh, "Advertising failed to start"
					    " (err %d)\n", err);
				return -ENOEXEC;
			}

			printk("Advertising successfully started\n");
		}

		shell_print(sh, "Start HRS simulation");
		hrs_simulate = true;
	} else if (!strcmp(argv[1], "off")) {
		shell_print(sh, "Stop HRS simulation");

		if (hrs_registered && IS_ENABLED(CONFIG_BT_BROADCASTER)) {
			bt_le_adv_stop();
		}

		hrs_simulate = false;
	} else {
		shell_print(sh, "Incorrect value: %s", argv[1]);
		shell_help(sh);
		return -ENOEXEC;
	}

	return 0;
}
#endif /* CONFIG_BT_HRS */

#define HELP_NONE "[none]"
#define HELP_ADDR_LE "<address: P:XX:XX:XX:XX:XX:XX or R:XX:XX:XX:XX:XX:XX>"

SHELL_STATIC_SUBCMD_SET_CREATE(hrs_cmds,
#if defined(CONFIG_BT_HRS)
	SHELL_CMD_ARG(simulate, NULL,
		"register and simulate Heart Rate Service <value: on, off>",
		cmd_hrs_simulate, 2, 0),
#endif /* CONFIG_BT_HRS*/
	SHELL_SUBCMD_SET_END
);

static int cmd_hrs(const struct shell *sh, size_t argc, char **argv)
{
	shell_error(sh, "%s unknown parameter: %s", argv[0], argv[1]);

	return -ENOEXEC;
}

SHELL_CMD_ARG_REGISTER(hrs, &hrs_cmds, "Heart Rate Service shell commands",
		       cmd_hrs, 2, 0);

#if defined(CONFIG_BT_HRS)
static void hrs_notify(void)
{
	static uint8_t heartrate = 90U;

	/* Heartrate measurements simulation */
	heartrate++;
	if (heartrate == 160U) {
		heartrate = 90U;
	}

	bt_hrs_notify(heartrate);
}
#endif /* CONFIG_BT_HRS */

int main(void)
{
#if DT_NODE_HAS_COMPAT(DT_CHOSEN(zephyr_shell_uart), zephyr_cdc_acm_uart)
	const struct device *dev;
	uint32_t dtr = 0;

	dev = DEVICE_DT_GET(DT_CHOSEN(zephyr_shell_uart));
	if (!device_is_ready(dev)) {
		return 0;
	}

	while (!dtr) {
		uart_line_ctrl_get(dev, UART_LINE_CTRL_DTR, &dtr);
		k_sleep(K_MSEC(100));
	}
#endif

	printk("Type \"help\" for supported commands.");
	printk("Before any Bluetooth commands you must `bt init` to initialize"
	       " the stack.\n");

	while (1) {
		k_sleep(K_SECONDS(1));

#if defined(CONFIG_BT_HRS)
		/* Heartrate measurements simulation */
		if (hrs_simulate) {
			hrs_notify();
		}
#endif /* CONFIG_BT_HRS */
	}
}
```

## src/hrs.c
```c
/* Workaround build system bug that will put objects in source dir */
#include "../../../../samples/bluetooth/gatt/hrs.c"
```
